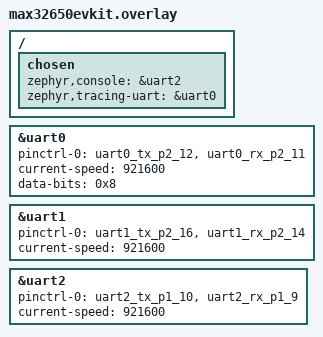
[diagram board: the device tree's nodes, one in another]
/ {
	chosen {
		zephyr,console = &uart2;
		zephyr,tracing-uart = &uart0;
	};
};

&uart0 {
	status = "okay";
	pinctrl-0 = < &uart0_tx_p2_12 &uart0_rx_p2_11 >;
	pinctrl-names = "default";
	current-speed = < 921600 >;
	data-bits = < 0x8 >;
};

&uart1 {
	status = "okay";
	pinctrl-0 = <&uart1_tx_p2_16 &uart1_rx_p2_14>;
	pinctrl-names = "default";
	current-speed = <921600>;
};

&uart2 {
	status = "okay";
	pinctrl-0 = <&uart2_tx_p1_10 &uart2_rx_p1_9>;
	pinctrl-names = "default";
	current-speed = <921600>;
};
